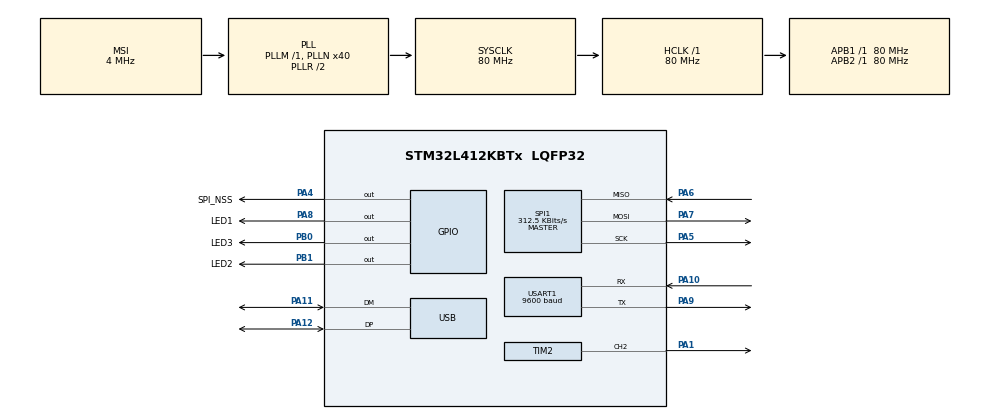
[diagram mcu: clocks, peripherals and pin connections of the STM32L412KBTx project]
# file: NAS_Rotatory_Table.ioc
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Dma.Request0=USART1_TX
Dma.Request1=USART1_RX
Dma.USART1_RX.1.Direction=DMA_PERIPH_TO_MEMORY
Dma.USART1_RX.1.Instance=DMA1_Channel5
Dma.USART1_RX.1.MemDataAlignment=DMA_MDATAALIGN_BYTE
Dma.USART1_RX.1.MemInc=DMA_MINC_ENABLE
Dma.USART1_RX.1.Mode=DMA_CIRCULAR
Dma.USART1_RX.1.PeriphDataAlignment=DMA_PDATAALIGN_BYTE
Dma.USART1_RX.1.PeriphInc=DMA_PINC_DISABLE
Dma.USART1_RX.1.Priority=DMA_PRIORITY_VERY_HIGH
Dma.USART1_TX.0.Direction=DMA_MEMORY_TO_PERIPH
Dma.USART1_TX.0.Instance=DMA1_Channel4
Dma.USART1_TX.0.MemDataAlignment=DMA_MDATAALIGN_BYTE
Dma.USART1_TX.0.MemInc=DMA_MINC_ENABLE
Dma.USART1_TX.0.Mode=DMA_NORMAL
Dma.USART1_TX.0.PeriphDataAlignment=DMA_PDATAALIGN_BYTE
Dma.USART1_TX.0.PeriphInc=DMA_PINC_DISABLE
Dma.USART1_TX.0.Priority=DMA_PRIORITY_LOW
FREERTOS.Tasks01=defaultTask,24,128,StartDefaultTask,Default,NULL,Dynamic,NULL,NULL
FREERTOS.configENABLE_FPU=1
FREERTOS.configTOTAL_HEAP_SIZE=10000
FREERTOS.configUSE_NEWLIB_REENTRANT=1
Mcu.Family=STM32L4
Mcu.Name=STM32L412KBTx
Mcu.Package=LQFP32
NVIC.DMA1_Channel4_IRQn=true\:6\:0\:true\:false\:true\:true\:false\:true\:true
NVIC.DMA1_Channel5_IRQn=true\:5\:0\:false\:false\:true\:true\:false\:true\:true
NVIC.PriorityGroup=NVIC_PRIORITYGROUP_4
NVIC.SPI1_IRQn=true\:5\:0\:false\:false\:true\:true\:true\:true\:true
NVIC.TIM1_UP_TIM16_IRQn=true\:15\:0\:false\:false\:true\:false\:false\:true\:true
NVIC.TimeBase=TIM1_UP_TIM16_IRQn
NVIC.TimeBaseIP=TIM16
NVIC.USART1_IRQn=true\:5\:0\:false\:false\:true\:true\:true\:true\:true
NVIC.USB_IRQn=true\:5\:0\:false\:false\:true\:true\:false\:true\:true
PA1.Signal=S_TIM2_CH2
PA10.Mode=Asynchronous
PA10.Signal=USART1_RX
PA11.Mode=Device
PA11.Signal=USB_DM
PA12.Mode=Device
PA12.Signal=USB_DP
PA4.GPIO_Label=SPI_NSS
PA4.Signal=GPIO_Output
PA5.Mode=Full_Duplex_Master
PA5.Signal=SPI1_SCK
PA6.Mode=Full_Duplex_Master
PA6.Signal=SPI1_MISO
PA7.Mode=Full_Duplex_Master
PA7.Signal=SPI1_MOSI
PA8.GPIO_Label=LED1
PA8.Signal=GPIO_Output
PA9.GPIO_ModeDefaultPP=GPIO_MODE_AF_PP
PA9.Mode=Asynchronous
PA9.Signal=USART1_TX
PB0.GPIO_Label=LED3
PB0.Signal=GPIO_Output
PB1.GPIO_Label=LED2
PB1.Signal=GPIO_Output
ProjectManager.HeapSize=0x200
ProjectManager.StackSize=0x400
ProjectManager.TargetToolchain=STM32CubeIDE
RCC.ADCFreq_Value=80000000
RCC.AHBFreq_Value=80000000
RCC.APB1Freq_Value=80000000
RCC.APB1TimFreq_Value=80000000
RCC.APB2Freq_Value=80000000
RCC.APB2TimFreq_Value=80000000
RCC.CK48CLockSelection=RCC_USBCLKSOURCE_HSI48
RCC.CortexFreq_Value=80000000
RCC.HCLKFreq_Value=80000000
RCC.HSE_VALUE=8000000
RCC.HSI48_VALUE=48000000
RCC.HSI_VALUE=16000000
RCC.LSE_VALUE=32768
RCC.MSI_VALUE=4000000
RCC.PLLN=40
RCC.PLLQ=RCC_PLLQ_DIV8
RCC.PREFETCH_ENABLE=1
RCC.SYSCLKFreq_VALUE=80000000
RCC.SYSCLKSource=RCC_SYSCLKSOURCE_PLLCLK
RCC.USBFreq_Value=48000000
RCC.VCOOutputFreq_Value=160000000
SH.S_TIM2_CH2.0=TIM2_CH2,PWM Generation2 CH2
SPI1.BaudRatePrescaler=SPI_BAUDRATEPRESCALER_256
SPI1.CLKPhase=SPI_PHASE_2EDGE
SPI1.CLKPolarity=SPI_POLARITY_HIGH
SPI1.CalculateBaudRate=312.5 KBits/s
SPI1.DataSize=SPI_DATASIZE_8BIT
SPI1.Direction=SPI_DIRECTION_2LINES
SPI1.Mode=SPI_MODE_MASTER
SPI1.VirtualType=VM_MASTER
TIM2.Channel-PWM\ Generation2\ CH2=TIM_CHANNEL_2
TIM2.Period=2000
TIM2.Prescaler=1
USART1.BaudRate=9600
USART1.Parity=PARITY_EVEN
USART1.VirtualMode-Asynchronous=VM_ASYNC
USART1.WordLength=WORDLENGTH_9B
USB_DEVICE.CLASS_NAME_FS=CDC
USB_DEVICE.MANUFACTURER_STRING=RTC-ATC Groi
USB_DEVICE.PRODUCT_STRING_CDC_FS=NAS Virtual ComPort
USB_DEVICE.VirtualMode=Cdc
USB_DEVICE.VirtualModeFS=Cdc_FS
VP_FREERTOS_VS_CMSIS_V2.Mode=CMSIS_V2
VP_SYS_VS_tim16.Mode=TIM16
VP_USB_DEVICE_VS_USB_DEVICE_CDC_FS.Mode=CDC_FS
board=custom

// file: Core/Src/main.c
/* USER CODE BEGIN Header */
/**
  ******************************************************************************
  * @file           : main.c
  * @brief          : Main program body
  ******************************************************************************
  * @attention
  *
  * Copyright (c) 2025 STMicroelectronics.
  * All rights reserved.
  *
  * This software is licensed under terms that can be found in the LICENSE file
  * in the root directory of this software component.
  * If no LICENSE file comes with this software, it is provided AS-IS.
  *
  ******************************************************************************
  */
/* USER CODE END Header */
#include "main.h"
#include "cmsis_os.h"
#include "dma.h"
#include "spi.h"
#include "tim.h"
#include "usart.h"
#include "usb_device.h"
#include "gpio.h"

void SystemClock_Config(void);
void MX_FREERTOS_Init(void);

int main(void)
{

  /* MCU Configuration--------------------------------------------------------*/

  /* Reset of all peripherals, Initializes the Flash interface and the Systick. */
  HAL_Init();

  /* Configure the system clock */
  SystemClock_Config();

  /* Initialize all configured peripherals */
  MX_GPIO_Init();
  MX_DMA_Init();
  MX_SPI1_Init();
  MX_TIM2_Init();
  MX_USART1_UART_Init();

  /* Init scheduler */
  osKernelInitialize();

  /* Call init function for freertos objects (in cmsis_os2.c) */
  MX_FREERTOS_Init();

  /* Start scheduler */
  osKernelStart();

  /* We should never get here as control is now taken by the scheduler */

  /* Infinite loop */
  while (1)
  {

  }
}

void SystemClock_Config(void)
{
  RCC_OscInitTypeDef RCC_OscInitStruct = {0};
  RCC_ClkInitTypeDef RCC_ClkInitStruct = {0};

  /** Configure the main internal regulator output voltage
  */
  if (HAL_PWREx_ControlVoltageScaling(PWR_REGULATOR_VOLTAGE_SCALE1) != HAL_OK)
  {
    Error_Handler();
  }

  /** Initializes the RCC Oscillators according to the specified parameters
  * in the RCC_OscInitTypeDef structure.
  */
  RCC_OscInitStruct.OscillatorType = RCC_OSCILLATORTYPE_HSI48|RCC_OSCILLATORTYPE_MSI;
  RCC_OscInitStruct.HSI48State = RCC_HSI48_ON;
  RCC_OscInitStruct.MSIState = RCC_MSI_ON;
  RCC_OscInitStruct.MSICalibrationValue = 0;
  RCC_OscInitStruct.MSIClockRange = RCC_MSIRANGE_6;
  RCC_OscInitStruct.PLL.PLLState = RCC_PLL_ON;
  RCC_OscInitStruct.PLL.PLLSource = RCC_PLLSOURCE_MSI;
  RCC_OscInitStruct.PLL.PLLM = 1;
  RCC_OscInitStruct.PLL.PLLN = 40;
  RCC_OscInitStruct.PLL.PLLQ = RCC_PLLQ_DIV8;
  RCC_OscInitStruct.PLL.PLLR = RCC_PLLR_DIV2;
  if (HAL_RCC_OscConfig(&RCC_OscInitStruct) != HAL_OK)
  {
    Error_Handler();
  }

  /** Initializes the CPU, AHB and APB buses clocks
  */
  RCC_ClkInitStruct.ClockType = RCC_CLOCKTYPE_HCLK|RCC_CLOCKTYPE_SYSCLK
                              |RCC_CLOCKTYPE_PCLK1|RCC_CLOCKTYPE_PCLK2;
  RCC_ClkInitStruct.SYSCLKSource = RCC_SYSCLKSOURCE_PLLCLK;
  RCC_ClkInitStruct.AHBCLKDivider = RCC_SYSCLK_DIV1;
  RCC_ClkInitStruct.APB1CLKDivider = RCC_HCLK_DIV1;
  RCC_ClkInitStruct.APB2CLKDivider = RCC_HCLK_DIV1;

  if (HAL_RCC_ClockConfig(&RCC_ClkInitStruct, FLASH_LATENCY_4) != HAL_OK)
  {
    Error_Handler();
  }
}

void HAL_TIM_PeriodElapsedCallback(TIM_HandleTypeDef *htim)
{
  if (htim->Instance == TIM16)
  {
    HAL_IncTick();
  }
}

void Error_Handler(void)
{
  __disable_irq();
  while (1)
  {
  }
}

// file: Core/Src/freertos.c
/* USER CODE BEGIN Header */
/**
  ******************************************************************************
  * File Name          : freertos.c
  * Description        : Code for freertos applications
  ******************************************************************************
  * @attention
  *
  * Copyright (c) 2025 STMicroelectronics.
  * All rights reserved.
  *
  * This software is licensed under terms that can be found in the LICENSE file
  * in the root directory of this software component.
  * If no LICENSE file comes with this software, it is provided AS-IS.
  *
  ******************************************************************************
  */
/* USER CODE END Header */

#include "FreeRTOS.h"
#include "task.h"
#include "main.h"
#include "cmsis_os.h"
#include "usbd_cdc_if.h"
/* USER CODE BEGIN Includes */
#include "NRT_Task.h"
/* USER CODE END Includes */

/* Definitions for defaultTask */
osThreadId_t defaultTaskHandle;
const osThreadAttr_t defaultTask_attributes = {
  .name = "defaultTask",
  .stack_size = 128 * 4,
  .priority = (osPriority_t) osPriorityNormal,
};

void StartDefaultTask(void *argument);

extern void MX_USB_DEVICE_Init(void);
void MX_FREERTOS_Init(void); /* (MISRA C 2004 rule 8.1) */

void MX_FREERTOS_Init(void) {

  /* Create the thread(s) */
  /* creation of defaultTask */
 // defaultTaskHandle = osThreadNew(StartDefaultTask, NULL, &defaultTask_attributes);

  /* USER CODE BEGIN RTOS_THREADS */
  /* add threads, ... */
	xTaskCreate(NRT_Task, "NRT", 256, NULL, 0, NULL);

	/* USER CODE END RTOS_THREADS */

}

void StartDefaultTask(void *argument)
{
  /* init code for USB_DEVICE */
  MX_USB_DEVICE_Init();
  /* USER CODE BEGIN StartDefaultTask */
  /* Infinite loop */
  for(;;)
  {
	CDC_Transmit_FS("Hola\r\n",6);
    osDelay(500);
  }
  /* USER CODE END StartDefaultTask */
}
